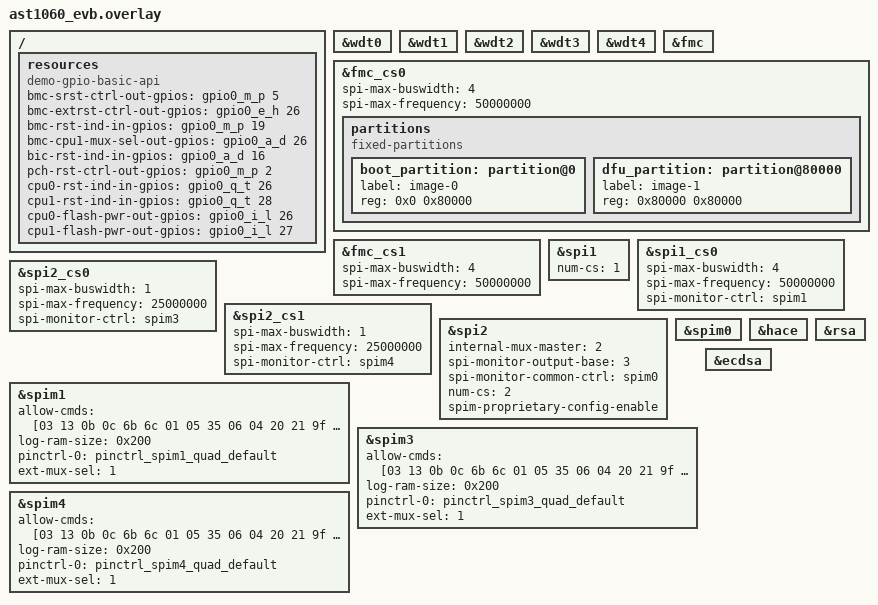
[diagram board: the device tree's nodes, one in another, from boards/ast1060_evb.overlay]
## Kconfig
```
# Copyright (c) 2021 ASPEED Technology Inc. <chin-ting_kuo@aspeedtech.com>
# SPDX-License-Identifier: Apache-2.0

config WDT_DEMO_ASPEED
	default n
	bool "ASPEED WDT demo"
	help
	  Enable ASPEED WDT demo behaviors.

config ASPEED_DC_SCM
	default y
	bool "ASPEED DC-SCM board"
	help
	  Enable ASPEED DC-SCM board basic settings.

source "Kconfig.zephyr"
```

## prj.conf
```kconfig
CONFIG_GPIO=y
CONFIG_SPI=y
CONFIG_THREAD_RUNTIME_STATS=y
CONFIG_GPIO_SHELL=y
CONFIG_HEAP_MEM_POOL_SIZE=16384
CONFIG_COMMON_LIBC_MALLOC_ARENA_SIZE=147456
CONFIG_REBOOT=y
CONFIG_POSIX_CLOCK=y
CONFIG_STACK_SENTINEL=y
CONFIG_LOG=y
CONFIG_SHELL=y
CONFIG_SHELL_BACKEND_SERIAL_INIT_PRIORITY=99
CONFIG_PFR_FLOW_CTRL_AST1060=y
CONFIG_SHELL_STACK_SIZE=4096
CONFIG_FLASH=y
CONFIG_SPI_NOR_MULTI_DEV=y
CONFIG_FLASH_SHELL=y
CONFIG_FLASH_MAP=y
CONFIG_FLASH_PAGE_LAYOUT=y
```

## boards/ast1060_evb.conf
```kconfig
CONFIG_GPIO_ASPEED=y
CONFIG_SPI_ASPEED=y
CONFIG_SPI_MONITOR_ASPEED=y
CONFIG_SPI_MONITOR_SHELL_ASPEED=y
CONFIG_SPI_NOR_ADDR_MODE_FALLBACK_DISABLED=y
CONFIG_PFR_SHELL_ASPEED=y
CONFIG_SHELL_ARGC_MAX=70
CONFIG_WATCHDOG=y
CONFIG_ABR_FLOW_CTRL_ASPEED=y
CONFIG_FLASH=y
CONFIG_FLASH_PAGE_LAYOUT=y
# CONFIG_SPI_NOR is not set
CONFIG_REBOOT=y
CONFIG_DYNAMIC_INTERRUPTS=y
```

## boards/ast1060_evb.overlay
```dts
/ {
	resources {
		compatible = "demo-gpio-basic-api";
		bmc-srst-ctrl-out-gpios = <&gpio0_m_p 5 0>; /* GPIO_M5 */
		bmc-extrst-ctrl-out-gpios = <&gpio0_e_h 26 0>; /* GPIO_H2 */
		bmc-rst-ind-in-gpios = <&gpio0_m_p 19 0>; /* GPIO_O3 */
		bmc-cpu1-mux-sel-out-gpios = <&gpio0_a_d 26 0>; /* GPIO_D2 */
		bic-rst-ind-in-gpios = <&gpio0_a_d 16 0>; /* GPIO_C0 */
		pch-rst-ctrl-out-gpios = <&gpio0_m_p 2 0>; /* GPIO_M2 */
		cpu0-rst-ind-in-gpios = <&gpio0_q_t 26 0>; /* GPIO_T2 */
		cpu1-rst-ind-in-gpios = <&gpio0_q_t 28 0>; /* GPIO_T4 */
		cpu0-flash-pwr-out-gpios = <&gpio0_i_l 26 0>; /* GPIO_L2 */
		cpu1-flash-pwr-out-gpios = <&gpio0_i_l 27 0>; /* GPIO_L3 */
	};
};

&wdt0 {
	status = "okay";
};

&wdt1 {
	status = "okay";
};

&wdt2 {
	status = "okay";
};

&wdt3 {
	status = "okay";
};

&wdt4 {
	status = "okay";
};

&fmc {
	status = "okay";
};

&fmc_cs0 {
	status = "okay";
	spi-max-buswidth = <4>;
	spi-max-frequency = <50000000>;

	partitions {
		compatible = "fixed-partitions";
		#address-cells = <1>;
		#size-cells = <1>;
		boot_partition: partition@0 {
			label = "image-0";
			reg = <0x0 0x80000>;
		};
		dfu_partition: partition@80000 {
		       label = "image-1";
		       reg = <0x80000 0x80000>;
	       };
	};
};

&fmc_cs1 {
	status = "okay";
	spi-max-buswidth = <4>;
	spi-max-frequency = <50000000>;
};

&spi1 {
	status = "okay";
	num-cs = <1>;
};

&spi1_cs0 {
	spi-max-buswidth = <4>;
	spi-max-frequency = <50000000>;
	spi-monitor-ctrl = <&spim1>;
	status = "okay";
};

/* Use AST1060 SPI2 as the internal SPI master to
 * to access the SPI flashes connected to SPI monitors
 * Here,
 * "SPI2_CS1" is used to access flash connected to SPI_Monitor_3,
 * "SPI2_CS2" is used to access flash connected to SPI_Monitor_4,
 */

&spi2_cs0 {
	spi-max-buswidth = <1>;
	spi-max-frequency = <25000000>;
	spi-monitor-ctrl = <&spim3>;
	status = "okay";
};

&spi2_cs1 {
	spi-max-buswidth = <1>;
	spi-max-frequency = <25000000>;
	spi-monitor-ctrl = <&spim4>;
	status = "okay";
};

&spi2 {
	internal-mux-master = <2>;
	spi-monitor-output-base = <3>;
	spi-monitor-common-ctrl = <&spim0>;

	num-cs = <2>;
	status = "okay";

	spim-proprietary-config-enable;
};

&spim0 {
	status = "okay";
};

&spim1 {
	allow-cmds = [03 13 0b 0c 6b 6c 01 05 35 06 04 20 21 9f 5a b7 e9 32 34 d8 dc 02 12 3b 3c
				  70 50 eb ec c2];
	log-ram-size = <0x200>;
	pinctrl-0 = <pinctrl_spim1_quad_default>;
	pinctrl-names = "default";
	ext-mux-sel = <1>;
	status = "okay";
};

&spim3 {
	allow-cmds = [03 13 0b 0c 6b 6c 01 05 35 06 04 20 21 9f 5a b7 e9 32 34 d8 dc 02 12 3b 3c
				  70 50 eb ec c2];
	log-ram-size = <0x200>;
	pinctrl-0 = <pinctrl_spim3_quad_default>;
	pinctrl-names = "default";
	ext-mux-sel = <1>;
	status = "okay";
};

&spim4 {
	allow-cmds = [03 13 0b 0c 6b 6c 01 05 35 06 04 20 21 9f 5a b7 e9 32 34 d8 dc 02 12 3b 3c
				  70 50 eb ec c2];
	log-ram-size = <0x200>;
	pinctrl-0 = <pinctrl_spim4_quad_default>;
	pinctrl-names = "default";

	ext-mux-sel = <1>;
	status = "okay";
};

&hace {
	status = "okay";
};

&rsa {
	status = "okay";
};

&ecdsa {
	status = "okay";
};
```

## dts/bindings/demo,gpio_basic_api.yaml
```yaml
#
# Copyright (c) 2019 Nordic Semiconductor ASA
# Copyright (c) 2021 ASPEED Technology Inc.
#
# SPDX-License-Identifier: Apache-2.0
#

description: |
    This binding provides resources required to build and run the
    samples/ast1060_evb/demo in Zephyr.

compatible: "demo-gpio-basic-api"

properties:
    bmc-srst-ctrl-out-gpios:
        type: phandle-array
        required: false
        description: Control BMC SRST# signal.

    bmc-extrst-ctrl-out-gpios:
        type: phandle-array
        required: false
        description: Control BMC EXTRST# signal.

    bmc-rst-ind-in-gpios:
        type: phandle-array
        required: false
        description: Detect or monitor BMC reset indicator.

    bmc-cpu1-mux-sel-out-gpios:
        type: phandle-array
        required: false
        description: |
          Control the MUX selection pin which determains
          SPI flash signal from BMC or CPU1.
          0: CPU1
          1: BMC or BIC

    bic-rst-ind-in-gpios:
        type: phandle-array
        required: false
        description: Detect or monitor BIC reset indicator.

    pch-rst-ctrl-out-gpios:
        type: phandle-array
        required: false
        description: Control PCH reset signal.

    cpu0-rst-ind-in-gpios:
        type: phandle-array
        required: false
        description: Detect CPU0 reset indicator.

    cpu1-rst-ind-in-gpios:
        type: phandle-array
        required: false
        description: Detect CPU1 reset indicator.

    cpu0-flash-pwr-out-gpios:
        type: phandle-array
        required: false
        description: PCH CPU0 SPI flash power control.

    cpu1-flash-pwr-out-gpios:
        type: phandle-array
        required: false
        description: PCH CPU1 SPI flash power control.
```

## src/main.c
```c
/*
 * Copyright (c) 2021 ASPEED Technology Inc.
 *
 * SPDX-License-Identifier: Apache-2.0
 */

#include <zephyr/kernel.h>
#include <zephyr/sys/printk.h>
#include <zephyr/drivers/misc/aspeed/abr_aspeed.h>
#include <zephyr/drivers/misc/aspeed/pfr_aspeed.h>
#include <soc.h>

extern struct k_work rst_work;

void demo_spim_irq_init(void);
void demo_wdt(void);
void aspeed_dcscm_rst_demo(struct k_work *item);
void rst_ind_gpio_event_register(void);
void aspeed_dcscm_i2c_flt_demo(void);
void aspeed_dcscm_swmbx_demo(void);

int main(void)
{
	printk("%s demo\n", CONFIG_BOARD);
	aspeed_print_sysrst_info();
	disable_abr_wdt();

	/* reset BMC and PCH first */
	pfr_bmc_srst_enable_ctrl(true);
	pfr_bmc_extrst_enable_ctrl(true);
	pfr_pch_rst_enable_ctrl(true);

	demo_spim_irq_init();

	aspeed_dcscm_rst_demo(NULL);

	rst_ind_gpio_event_register();
	k_work_init(&rst_work, aspeed_dcscm_rst_demo);

#if CONFIG_I2C_PFR_FILTER
	aspeed_dcscm_i2c_flt_demo();
#endif

#if CONFIG_PFR_SW_MAILBOX
	aspeed_dcscm_swmbx_demo();
#endif

	/* the following demo part should be allocated
	 * at the final step of main function.
	 */
#if CONFIG_WDT_DEMO_ASPEED
	demo_wdt();
#endif

	return 0;
}
```

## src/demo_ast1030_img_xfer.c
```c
/*
 * Copyright (c) 2022 ASPEED Technology Inc.
 *
 * SPDX-License-Identifier: Apache-2.0
 */

#include <zephyr.h>
#include <stdlib.h>
#include <sys/printk.h>
#include <drivers/misc/aspeed/pfr_aspeed.h>
#include <drivers/gpio.h>
#include <drivers/uart.h>
#include <drivers/flash.h>

#define BIN_BUFFER_SZ 0x2000
#define BIC_IMAGE_OFFSET 0x80000

void ast1030_fwspi_ck_ctrl(uint8_t val);

static const struct uart_config uart_config = {
	.baudrate = 115200,
	.parity = UART_CFG_PARITY_NONE,
	.stop_bits = UART_CFG_STOP_BITS_1,
	.data_bits = UART_CFG_DATA_BITS_8,
	.flow_ctrl = UART_CFG_FLOW_CTRL_NONE,
};

int ast1030_img_xfer(void)
{
	const struct device *uart_dev, *flash_dev;
	uint32_t flash_offset, binary_size, xfer_size;
	uint8_t *binary_buffer = NULL;
	int i;
	int ret = 0;

	/* release  reset of UART1 */
	sys_write32(0xa00, 0x7e789098);

	uart_dev = device_get_binding("UART_1");
	if (!uart_dev) {
		printk("bin_xfer: UART device not found\n");
		ret = -EINVAL;
		goto end;
	}

	flash_dev = device_get_binding("fmc_cs0");
	if (!flash_dev) {
		printk("bin_xfer: flash device not found\n");
		ret = -EINVAL;
		goto end;
	}

	uart_configure(uart_dev, &uart_config);

	flash_offset = BIC_IMAGE_OFFSET;
	binary_buffer = malloc(BIN_BUFFER_SZ);
	if (!binary_buffer) {
		printk("bin_xfer: fail to alloc buffer\n");
		ret = -ENOSR;
		goto end;
	}

	ret = flash_read(flash_dev, flash_offset, binary_buffer, 4);
	if (ret != 0) {
		printk("bin_xfer: fail to read flash\n");
		ret = -ECANCELED;
		goto end;
	}

	binary_size = ((uint32_t *)binary_buffer)[0] + 4;

	printk("bin_xfer: uart boot binary size = %d\n", binary_size);

	printk("release BMC reset...\n");
	ast1030_fwspi_ck_ctrl(1);
	pfr_bmc_srst_enable_ctrl(false);
	pfr_bmc_extrst_enable_ctrl(false);

	if (binary_size > 256 * 1024) {
		printk("bin_xfer: invalid image size %d, skip transfer.\n", binary_size);
		ret = 0;
		goto end;
	}

	printk("bin_xfer: transfer ast1030 image....\n");

	while (binary_size) {
		xfer_size = (binary_size >= BIN_BUFFER_SZ) ? BIN_BUFFER_SZ : binary_size;
		ret = flash_read(flash_dev, flash_offset, binary_buffer, xfer_size);
		if (ret != 0) {
			printk("bin_xfer: fail to read flash (in progress)\n");
			ret = -ECANCELED;
			goto end;
		}

		for (i = 0; i < xfer_size; i++)
			uart_poll_out(uart_dev, binary_buffer[i]);

		binary_size -= xfer_size;
		flash_offset += xfer_size;
	}

end:
	if (binary_buffer)
		free(binary_buffer);

	return ret;
}
```

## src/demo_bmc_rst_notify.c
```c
/*
 * Copyright (c) 2021 - 2023 ASPEED Technology Inc.
 *
 * SPDX-License-Identifier: Apache-2.0
 */

#include <zephyr/kernel.h>
#include <zephyr/sys/printk.h>
#include <zephyr/drivers/misc/aspeed/pfr_aspeed.h>
#include "demo_gpio.h"

static struct gpio_callback gpio_cb[RST_IND_NUM];
struct k_work rst_work;

static void rst_ind_callback(const struct device *dev,
		       struct gpio_callback *gpio_cb, uint32_t pins)
{
	/* reset BMC and PCH first */
	pfr_bmc_extrst_enable_ctrl(true);
	pfr_bmc_srst_enable_ctrl(true);
	pfr_pch_rst_enable_ctrl(true);

	k_work_submit(&rst_work);

	ARG_UNUSED(*gpio_cb);
	ARG_UNUSED(pins);
}

void rst_ind_gpio_event_register(void)
{
	int ret;
	const struct device *gpio_devs[RST_IND_NUM] = {
			BMC_RSTIND_GPIO_DEV,
			BIC_RSTIND_GPIO_DEV,
			CPU0_RSTIND_GPIO_DEV,
			CPU1_RSTIND_GPIO_DEV,
	};
	gpio_pin_t gpio_pin[RST_IND_NUM] = {
			BMC_RSTIND_GPIO_PIN_IN,
			BIC_RSTIND_GPIO_PIN_IN,
			CPU0_RSTIND_GPIO_PIN_IN,
			CPU1_RSTIND_GPIO_PIN_IN
	};
	int i;

	for (i = 0; i < RST_IND_NUM; i++) {
		ret = gpio_pin_interrupt_configure(gpio_devs[i], gpio_pin[i],
						   GPIO_INT_DISABLE);
		if (ret != 0) {
			printk("demo_err: cannot configure GPIO INT(disabled).\n");
			return;
		}

		ret = gpio_pin_configure(gpio_devs[i], gpio_pin[i], GPIO_INPUT);
		if (ret != 0) {
			printk("demo_err: cannot configure gpio device.\n");
			return;
		}

		gpio_init_callback(&gpio_cb[i], rst_ind_callback, BIT(gpio_pin[i]));
		ret = gpio_add_callback(gpio_devs[i], &gpio_cb[i]);
		if (ret != 0) {
			printk("demo_err: cannot add gpio callback.\n");
			return;
		}

		ret = gpio_pin_interrupt_configure(gpio_devs[i], gpio_pin[i],
						   GPIO_INT_EDGE_TO_INACTIVE);
		if (ret != 0) {
			printk("demo_err: cannot configure GPIO INT(1->0).\n");
			return;
		}
	}
}
```

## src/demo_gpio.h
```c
/*
 * Copyright (c) 2021 - 2023 ASPEED Technology Inc.
 *
 * SPDX-License-Identifier: Apache-2.0
 */

#ifndef __DEMO_GPIO_H__
#define __DEMO_GPIO_H__

#include <zephyr/kernel.h>
#include <zephyr/drivers/gpio.h>
#include <zephyr/sys/util.h>

#if DT_NODE_HAS_STATUS(DT_INST(0, demo_gpio_basic_api), okay)
#define RST_IND_NUM 4

#define BMC_RSTIND_GPIO_DEV \
			DEVICE_DT_GET(DT_GPIO_CTLR_BY_IDX(DT_INST(0, demo_gpio_basic_api), \
			bmc_rst_ind_in_gpios, 0))
#define BMC_RSTIND_GPIO_PIN_IN \
			DT_GPIO_PIN_BY_IDX(DT_INST(0, demo_gpio_basic_api), \
			bmc_rst_ind_in_gpios, 0)

#define BIC_RSTIND_GPIO_DEV \
			DEVICE_DT_GET(DT_GPIO_CTLR_BY_IDX(DT_INST(0, demo_gpio_basic_api), \
			bic_rst_ind_in_gpios, 0))
#define BIC_RSTIND_GPIO_PIN_IN \
			DT_GPIO_PIN_BY_IDX(DT_INST(0, demo_gpio_basic_api), \
			bic_rst_ind_in_gpios, 0)

#define CPU0_RSTIND_GPIO_DEV \
			DEVICE_DT_GET(DT_GPIO_CTLR_BY_IDX(DT_INST(0, demo_gpio_basic_api), \
			cpu0_rst_ind_in_gpios, 0))
#define CPU0_RSTIND_GPIO_PIN_IN \
			DT_GPIO_PIN_BY_IDX(DT_INST(0, demo_gpio_basic_api), \
			cpu0_rst_ind_in_gpios, 0)

#define CPU1_RSTIND_GPIO_DEV \
			DEVICE_DT_GET(DT_GPIO_CTLR_BY_IDX(DT_INST(0, demo_gpio_basic_api), \
			cpu1_rst_ind_in_gpios, 0))
#define CPU1_RSTIND_GPIO_PIN_IN \
			DT_GPIO_PIN_BY_IDX(DT_INST(0, demo_gpio_basic_api), \
			cpu1_rst_ind_in_gpios, 0)
#else
#error Unsupported board
#endif

#endif /* __DEMO_GPIO_H__ */
```

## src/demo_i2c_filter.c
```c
/*
 * Copyright (c) 2021 - 2023 ASPEED Technology Inc.
 *
 * SPDX-License-Identifier: Apache-2.0
 */

#include <zephyr/kernel.h>
#include <zephyr/sys/printk.h>
#include <zephyr/drivers/i2c.h>
#include <zephyr/drivers/i2c/pfr/i2c_filter.h>

void aspeed_dcscm_i2c_flt_demo(void)
{
#if CONFIG_I2C_PFR_FILTER
	const struct device *pfr_flt_dev[3] = {NULL, NULL, NULL};
	struct ast_i2c_f_bitmap data_flt_pass[1] = {
	{
	{	/* pass all */
		0xFFFFFFFF, 0xFFFFFFFF, 0xFFFFFFFF, 0xFFFFFFFF,
		0xFFFFFFFF, 0xFFFFFFFF, 0xFFFFFFFF, 0xFFFFFFFF
	}
	}
	};
	int ret = 0, i = 0;

	/* get for dc-scm i2c flt */
	pfr_flt_dev[0] = device_get_binding("I2C_FILTER_0");
	if (!pfr_flt_dev[0]) {
		printk("I2C PFR : I2C FLT Device 0 not found.\n");
		return;
	}

	pfr_flt_dev[1] = device_get_binding("I2C_FILTER_1");
	if (!pfr_flt_dev[1]) {
		printk("I2C PFR : I2C FLT Device 1 not found.\n");
		return;
	}

	pfr_flt_dev[2] = device_get_binding("I2C_FILTER_2");
	if (!pfr_flt_dev[2]) {
		printk("I2C PFR : I2C FLT Device 2 not found.\n");
		return;
	}

	/* initial i2c filter as all block setting */
	for (i = 0; i < 3; i++) {
		if (pfr_flt_dev[i]) {
			ret = ast_i2c_filter_init(pfr_flt_dev[i]);
			if (ret) {
				printk("I2C PFR : FLT Device %d Initial failed.\n", i);
				return;
			}

			ret = ast_i2c_filter_en(pfr_flt_dev[i], 1, 1, 0, 0);
			if (ret) {
				printk("I2C PFR : FLT Device %d Enable / Disable failed.\n", i);
				return;
			}

			ret = ast_i2c_filter_default(pfr_flt_dev[i], 0);
			if (ret) {
				printk("I2C PFR : FLT Device %d Set Default failed.\n", i);
				return;
			}
		}
	}

	/* i2c0 is used as mailbox 0 and attached on filter 3, turn on it as all pass */
	ret = ast_i2c_filter_update(pfr_flt_dev[2], 0x0,
	0x60, &data_flt_pass[0]);
	if (ret) {
		printk("I2C PFR : I2C FLT Set update failed.\n");
		return;
	}
#endif
}
```

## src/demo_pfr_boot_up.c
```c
/*
 * Copyright (c) 2021 - 2023 ASPEED Technology Inc.
 *
 * SPDX-License-Identifier: Apache-2.0
 */

#include <zephyr/kernel.h>
#include <zephyr/sys/printk.h>
#include <zephyr/drivers/misc/aspeed/pfr_aspeed.h>
#include <zephyr/drivers/gpio.h>

#define HOST_SPI_MONITOR_NUM 3

int demo_spi_host_read(void);
void demo_rst_log_ptr(const struct device *dev);

void aspeed_dcscm_rst_demo(struct k_work *item)
{
	int ret;
	const struct device *spim_dev = NULL;
	uint32_t i;
	static char *spim_devs[HOST_SPI_MONITOR_NUM] = {
		"spim@1",
		"spim@3",
		"spim@4"
	};

	/* disable passthrough mode for other SPI monitors */
	for (i = 0; i < HOST_SPI_MONITOR_NUM; i++) {
		spim_dev = device_get_binding(spim_devs[i]);
		if (!spim_dev) {
			printk("demo_err: cannot get device, %s.\n", spim_devs[i]);
			return;
		}

		/* spim_rst_flash(spim_dev, 1000); */

		/* config all spi monitor as master mode */
		spim_ext_mux_config(spim_dev, 1);
	}

	/* emulate PFR reads each flash content for verification purpose */
	ret = demo_spi_host_read();
	if (ret)
		return;

	/* set up monitor mode for all SPI monitors */
	for (i = 0; i < HOST_SPI_MONITOR_NUM; i++) {
		spim_dev = device_get_binding(spim_devs[i]);
		if (!spim_dev) {
			printk("demo_err: cannot get device, %s.\n", spim_devs[i]);
			return;
		}

		ast1060_spim_sw_rst(spim_dev);
		demo_rst_log_ptr(spim_dev);

		/* config spim as SPI monitor */
		spim_ext_mux_config(spim_dev, 0);
	}

	/*
	 * wait for 50ms after configuring external MUX
	 * in order to get overall stable system.
	 */
	k_busy_wait(50000);

	pfr_bmc_srst_enable_ctrl(false);
	pfr_bmc_extrst_enable_ctrl(false);

	pfr_pch_rst_enable_ctrl(false);
	ARG_UNUSED(item);
}
```

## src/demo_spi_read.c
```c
/*
 * Copyright (c) 2021 - 2023 Aspeed Technology Inc.
 *
 * SPDX-License-Identifier: Apache-2.0
 */

#include <zephyr/drivers/flash.h>
#include <zephyr/drivers/spi_nor.h>
#include <zephyr/kernel.h>
#include <zephyr/sys/util.h>
#include <soc.h>
#include <stdlib.h>
#include <string.h>
#include <zephyr/kernel.h>

#define LOG_MODULE_NAME spi_read_demo

#include <zephyr/logging/log.h>
LOG_MODULE_REGISTER(LOG_MODULE_NAME);

#define SPI_FLASH_TEST_SECTOR_SIZE 0x1000
#define SPI_FLASH_TEST_SIZE SPI_FLASH_TEST_SECTOR_SIZE
#define SPI_FLASH_TEST_ARR_SIZE 0x1100

static uint8_t op_arr[SPI_FLASH_TEST_SIZE] NON_CACHED_BSS_ALIGN16;

#define HOST_SPI_MONITOR_NUM 5

static char *flash_devices[HOST_SPI_MONITOR_NUM] = {
	"fmc@0",
	"fmc@1",
	"spi1@0",
	"spi2@0",
	"spi2@1",
};

static void spi_flash_dump_buf(uint8_t *buf, uint32_t len)
{
	uint32_t i;

	for (i = 0; i < len; i++) {
		printk("%02x ", buf[i]);
		if (i % 16 == 15)
			printk("\n");
	}
	printk("\n");
}

/* Just demo read operation here */
int demo_spi_host_read(void)
{
	int ret = 0;
	const struct device *flash_dev;
	uint8_t *op_buf = NULL;
	uint32_t i;

	op_buf = (uint8_t *)op_arr;

	for (i = 0; i < HOST_SPI_MONITOR_NUM; i++) {
		flash_dev = device_get_binding(flash_devices[i]);
		if (!flash_dev) {
			LOG_ERR("No device named %s.", flash_devices[i]);
			return -ENOEXEC;
		}

		ret = spi_nor_rst_by_cmd(flash_dev);
		if (ret) {
			LOG_ERR("fail to reset flash %s", flash_devices[i]);
			goto end;
		}

		ret = flash_read(flash_dev, 0x0, op_buf, SPI_FLASH_TEST_SIZE);
		if (ret) {
			LOG_ERR("fail to read flash %s", flash_devices[i]);
			goto end;
		}

		printk("[%s]read result:\n", flash_devices[i]);
		spi_flash_dump_buf(op_buf, 4);
		spi_flash_dump_buf(op_buf + SPI_FLASH_TEST_SIZE - 4, 4);

		ret = spi_nor_config_4byte_mode(flash_dev, false);
		if (ret)
			goto end;
	}

	k_busy_wait(20000); /* 20ms */

end:

	return ret;
}
```

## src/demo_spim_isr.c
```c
/*
 * Copyright (c) 2021 - 2023 Aspeed Technology Inc.
 *
 * SPDX-License-Identifier: Apache-2.0
 */

#include <string.h>
#include <zephyr/kernel.h>
#include <zephyr/types.h>
#include <zephyr/sys/printk.h>
#include <zephyr/drivers/misc/aspeed/pfr_aspeed.h>
#include <zephyr/sys/sys_io.h>
#include <zephyr/sys/__assert.h>
#include <zephyr/sys/util.h>
#include <errno.h>

struct demo_spim_log_ctrl {
	struct k_work log_work;
	struct spim_log_info info;
	const struct device *dev;
	uint32_t cur_off;
	uint32_t pre_off;
};

struct k_sem sem_demo_log_op;
struct demo_spim_log_ctrl log_ctrls[4];
const struct device *spim_devs[4];

static void spim_log_parser(const struct device *dev, uint32_t idx, uint32_t log_val)
{

	switch ((log_val & 0x000c0000) >> 18) {
	case 0x0:
		/* block command */
		printk("[%s][b][%03d][cmd] %02xh\n",
				dev->name, idx, log_val & 0xFF);
		break;

	case 0x1:
		/* block write command */
		printk("[%s][b][%03d][w_addr] 0x%08x\n",
				dev->name, idx, (log_val & 0x3FFFF) << 14);
		break;

	case 0x2:
		/* block read command */
		printk("[%s][b][%03d][r_addr] 0x%08x\n",
				dev->name, idx, (log_val & 0x3FFFF) << 14);
		break;

	default:
		printk("[%s][%03d]invalid ctx: 0x%08x", dev->name, idx, log_val);
	}
}

void demo_rst_log_ptr(const struct device *dev)
{
	uint32_t ctrl_idx = spim_get_ctrl_idx(dev);

	if (IS_ENABLED(CONFIG_MULTITHREADING))
		k_sem_take(&sem_demo_log_op, K_FOREVER);

	log_ctrls[ctrl_idx - 1].pre_off = 0;

	if (IS_ENABLED(CONFIG_MULTITHREADING))
		k_sem_give(&sem_demo_log_op);
}

static void demo_spim_log_work(struct k_work *item)
{
	uint32_t i;
	struct demo_spim_log_ctrl *log_ctrl =
		CONTAINER_OF(item, struct demo_spim_log_ctrl, log_work);

	if (IS_ENABLED(CONFIG_MULTITHREADING))
		k_sem_take(&sem_demo_log_op, K_FOREVER);

	spim_get_log_info(log_ctrl->dev, &log_ctrl->info);

	log_ctrl->cur_off = log_ctrl->info.log_idx_reg;
	if (log_ctrl->cur_off < log_ctrl->pre_off) {
		for (i = log_ctrl->pre_off; i < log_ctrl->info.log_max_sz / 4; i++) {
			spim_log_parser(log_ctrl->dev, i,
				sys_read32(log_ctrl->info.log_ram_addr + i * 4));
		}

		log_ctrl->pre_off = 0;
	}

	for (i = log_ctrl->pre_off; i < log_ctrl->cur_off; i++) {
		spim_log_parser(log_ctrl->dev, i,
			sys_read32(log_ctrl->info.log_ram_addr + i * 4));
	}

	log_ctrl->pre_off = log_ctrl->cur_off;

	if (IS_ENABLED(CONFIG_MULTITHREADING))
		k_sem_give(&sem_demo_log_op);

	k_usleep(1);
}

static void demo_spim_isr_callback(const struct device *dev)
{
	uint32_t ctrl_idx = spim_get_ctrl_idx(dev);

	/* notice: the ctrl_idx is from 1 to 4 */
	k_work_submit(&log_ctrls[ctrl_idx - 1].log_work);
}

void demo_spim_irq_init(void)
{
	uint32_t i;
	static char *spim_dev_names[4] = {
		"spim@1",
		"spim@2",
		"spim@3",
		"spim@4"
	};

	if (IS_ENABLED(CONFIG_MULTITHREADING))
		k_sem_init(&sem_demo_log_op, 1, 1);

	memset(log_ctrls, 0x0, sizeof(struct demo_spim_log_ctrl));

	for (i = 0; i < 4; i++) {
		if (i == 1) {
			/* spim2 is not used on dc-scm board. */
			continue;
		}

		spim_devs[i] = device_get_binding(spim_dev_names[i]);
		if (!spim_devs[i]) {
			printk("demo_err: cannot get device, %s.\n", spim_dev_names[i]);
			return;
		}

		log_ctrls[i].dev = spim_devs[i];
		k_work_init(&log_ctrls[i].log_work, demo_spim_log_work);
		spim_isr_callback_install(spim_devs[i], demo_spim_isr_callback);
	}
}
```

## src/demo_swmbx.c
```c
/*
 * Copyright (c) 2022 - 2023 ASPEED Technology Inc.
 *
 * SPDX-License-Identifier: Apache-2.0
 */

#include <zephyr/kernel.h>
#include <zephyr/sys/printk.h>
#include <zephyr/drivers/i2c.h>
#include <zephyr/drivers/i2c/pfr/swmbx.h>

#define swmbx_thread_size 256
#define SWMBX_DELAY 100
/* static struct k_thread zswmbx_n_t; */
/* static struct k_thread zswmbx_f_t; */
struct k_sem sem_0_05, sem_0_45;
struct k_sem sem_1_35, sem_1_45;
struct k_sem sem_fifo_0E, sem_fifo_0F;

K_THREAD_STACK_DEFINE(swmbx_thread_n_s, swmbx_thread_size);
K_THREAD_STACK_DEFINE(swmbx_thread_f_s, swmbx_thread_size);

/* dcscm thread demo for swmbx notify */
void dcscm_swmbx_notify(void *a, void *b, void *c)
{
#if CONFIG_PFR_SW_MAILBOX
	printk("dcscm swmbx_notify successful.\n");

	while (1) {
		if (k_sem_take(&sem_0_05, K_MSEC(50)) == 0) {
			printk("dcscm : SEM_0_05 is taken!!\n");
		}

		if (k_sem_take(&sem_0_45, K_MSEC(50)) == 0) {
			printk("dcscm : SEM_0_45 is taken!!\n");
		}

		if (k_sem_take(&sem_1_35, K_MSEC(50)) == 0) {
			printk("dcscm : SEM_1_35 is taken!!\n");
		}

		if (k_sem_take(&sem_1_45, K_MSEC(50)) == 0) {
			printk("dcscm : SEM_1_45 is taken!!\n");
		}

		k_sleep(K_MSEC(SWMBX_DELAY));
	}
#endif
}

/* i2c thread demo for dcscm swmbx fifo */
void dcscm_swmbx_fifo(void *a, void *b, void *c)
{
#if CONFIG_PFR_SW_MAILBOX
	printk("dcscm swmbx: swmbx_fifo successful.\n");

	while (1) {
		if (k_sem_take(&sem_fifo_0E, K_MSEC(50)) == 0) {
			printk("dcscm : SEM_FIFO_0E is taken!!\n");
		}

		if (k_sem_take(&sem_fifo_0F, K_MSEC(50)) == 0) {
			printk("dcscm : SEM_FIFO_0F is taken!!\n");
		}

		k_sleep(K_MSEC(SWMBX_DELAY));
	}
#endif
}

void aspeed_dcscm_swmbx_demo(void)
{
#if CONFIG_PFR_SW_MAILBOX
	const struct device *swmbx_ctrl = NULL;
	const struct device *dev = NULL;
	k_tid_t pidn, pidf;
	int ret;

	/* swmbx ctrl devices binding*/
	swmbx_ctrl = device_get_binding("SWMBX");
	if (!swmbx_ctrl) {
		printk("I2C: SWMBX Controller not be found.\n");
		return;
	}

	if (swmbx_ctrl) {
		/* apply function enable */
		ret = swmbx_enable_behavior(swmbx_ctrl,
			(SWMBX_NOTIFY | SWMBX_FIFO), true);
		if (ret) {
			printk("I2C: Enable SWMBX function failed.\n");
			return;
		}

		/* swmbx notify usage */
		k_sem_init(&sem_0_05, 0, 1);
		k_sem_init(&sem_0_45, 0, 1);
		k_sem_init(&sem_1_35, 0, 1);
		k_sem_init(&sem_1_45, 0, 1);

		ret = swmbx_update_notify(swmbx_ctrl, 0x0, &sem_0_05,
		0x0, true);
		ret = swmbx_update_notify(swmbx_ctrl, 0x0, &sem_0_45,
		0x40, true);
		ret = swmbx_update_notify(swmbx_ctrl, 0x1, &sem_1_35,
		0x30, true);
		ret = swmbx_update_notify(swmbx_ctrl, 0x1, &sem_1_45,
		0x40, true);

		/* create thread to receive mbx notify */
		if (IS_ENABLED(CONFIG_MULTITHREADING)) {
			pidn = k_thread_create(&zswmbx_n_t,
						swmbx_thread_n_s,
						swmbx_thread_size,
						(k_thread_entry_t)dcscm_swmbx_notify,
						NULL, NULL, NULL,
						-1,
						0, K_NO_WAIT);
		}

		/* assign mbx fifo setting */
		k_sem_init(&sem_fifo_0E, 0, 1);
		k_sem_init(&sem_fifo_0F, 0, 1);

		ret = swmbx_update_fifo(swmbx_ctrl, &sem_fifo_0E,
		0, 0x0e, 0x8, SWMBX_FIFO_NOTIFY_STOP, true);
		if (ret) {
			printk("I2C: Apply fifo 0e fail.\n");
			return;
		}

		ret = swmbx_update_fifo(swmbx_ctrl, &sem_fifo_0F,
		1, 0x0f, 0x8, SWMBX_FIFO_NOTIFY_STOP, true);
		if (ret) {
			printk("I2C: Apply fifo 0f fail.\n");
			return;
		}

		/* create thread to receive mbx fifo */
		if (IS_ENABLED(CONFIG_MULTITHREADING)) {
			pidf = k_thread_create(&zswmbx_f_t,
						  swmbx_thread_f_s,
						  swmbx_thread_size,
						  (k_thread_entry_t)dcscm_swmbx_fifo,
						  NULL, NULL, NULL,
						  -1,
						  0, K_NO_WAIT);
		}
	}

	/* register swmbx device 0 (bmc ast2600)/2 (cpu0)*/
	dev = device_get_binding("SWMBX_SLAVE_0");
	if (!dev) {
		printk("I2C: SWMBX Slave 0 not be found.\n");
		return;
	}
	i2c_slave_driver_register(dev);

	dev = device_get_binding("SWMBX_SLAVE_2");
	if (!dev) {
		printk("I2C: SWMBX Slave 2 not be found.\n");
		return;
	}
	i2c_slave_driver_register(dev);
#endif
}
```

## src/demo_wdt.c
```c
/*
 * Copyright (c) 2021 - 2023 ASPEED Technology Inc.
 *
 * SPDX-License-Identifier: Apache-2.0
 */

#include <zephyr/kernel.h>
#include <zephyr/types.h>
#include <zephyr/sys/printk.h>
#include <zephyr/drivers/misc/aspeed/pfr_aspeed.h>
#include <zephyr/sys/sys_io.h>
#include <zephyr/sys/__assert.h>
#include <zephyr/sys/util.h>
#include <errno.h>
#include <zephyr/drivers/watchdog.h>
#include <soc.h>

#if CONFIG_WDT_DEMO_ASPEED
static void demo_wdt_callback(const struct device *dev, int channel_id)
{
	printk("[%s] timeout is triggered.\n", dev->name);
}

void demo_wdt(void)
{
	struct wdt_timeout_cfg wdt_config;
	const struct device *wdt3_dev;
	const struct device *wdt4_dev;
	int ret;
	uint32_t count = 0;

	printk("wdt demo started.\n");

	wdt3_dev = device_get_binding("wdt@3");
	if (!wdt3_dev) {
		printk("demo_err: cannot find wdt3 device.\n");
		return;
	}

	wdt4_dev = device_get_binding("wdt@4");
	if (!wdt3_dev) {
		printk("demo_err: cannot find wdt4 device.\n");
		return;
	}

	wdt_config.window.min = 0U;
	wdt_config.window.max = 1000; /* 1 s */
	wdt_config.callback = demo_wdt_callback;
	ret = wdt_install_timeout(wdt3_dev, &wdt_config);
	if (ret != 0) {
		printk("demo_err: fail to install wdt3 timeout.\n");
		return;
	}

	wdt_config.window.min = 0U;
	wdt_config.window.max = 3000; /* 3s */
	wdt_config.callback = NULL;
	ret = wdt_install_timeout(wdt4_dev, &wdt_config);
	if (ret != 0) {
		printk("demo_err: fail to install wdt4 timeout.\n");
		return;
	}

	ret = wdt_setup(wdt3_dev, WDT_FLAG_RESET_NONE);
	if (ret != 0) {
		printk("demo_err: fail to setup wdt3.\n");
		return;
	}

	ret = wdt_setup(wdt4_dev, WDT_FLAG_RESET_CPU_CORE);
	if (ret != 0) {
		printk("demo_err: fail to setup wdt4.\n");
		return;
	}

	while (1) {
		if (count == 10) {
			printk("wdt_demo getting stuck...\n");
			k_sleep(K_FOREVER);
		}

		printk("wdt_demo ... %d\n", count);

		wdt_feed(wdt3_dev, 0);
		wdt_feed(wdt4_dev, 0);
		if (count < 5)
			k_sleep(K_MSEC(500));
		else
			k_sleep(K_MSEC(2000));

		count++;
	}
}
#endif

static void demo_wdt_background_thread(void)
{
	int ret = 0;
	const struct device *wdt2_dev = NULL;
	struct wdt_timeout_cfg wdt_config;

	wdt2_dev = device_get_binding("wdt@2");
	if (!wdt2_dev) {
		printk("demo_err: cannot find wdt2 device.\n");
		return;
	}

	wdt_config.window.min = 0U;
	wdt_config.window.max = 20000; /* 20s */
	wdt_config.callback = NULL;
	ret = wdt_install_timeout(wdt2_dev, &wdt_config);
	if (ret != 0) {
		printk("demo_err: fail to install wdt2 timeout.\n");
		return;
	}

	ret = wdt_setup(wdt2_dev, WDT_FLAG_RESET_CPU_CORE);
	if (ret != 0) {
		printk("demo_err: fail to setup wdt2.\n");
		return;
	}

	while (1) {
#if CONFIG_WDT_DEMO_ASPEED
		printk("wdt_demo thread still alive...\n");
#endif
		wdt_feed(wdt2_dev, 0);
		k_sleep(K_MSEC(3000));
	}
}

K_THREAD_DEFINE(wdt_background, 1024, demo_wdt_background_thread,
	NULL, NULL, NULL, -1, 0, 1000);
```
